# ATSAMA5D26 register map
Vendor: Microchip Technology; Series: SAMA5D2; File version: 0
Registers are 32-bit, read-write, reset 0x0 unless marked. A register's access mark holds for its fields unless they carry their own. Offsets are from the block's base; [hi:lo] are bit positions; {n}, {i} and the like mark numbered series.

## CLASSD — Audio Class D Amplifier (CLASSD)
Base 0xFC048000
0x00 CR wo — Control Register
  [0] SWRST — Software Reset
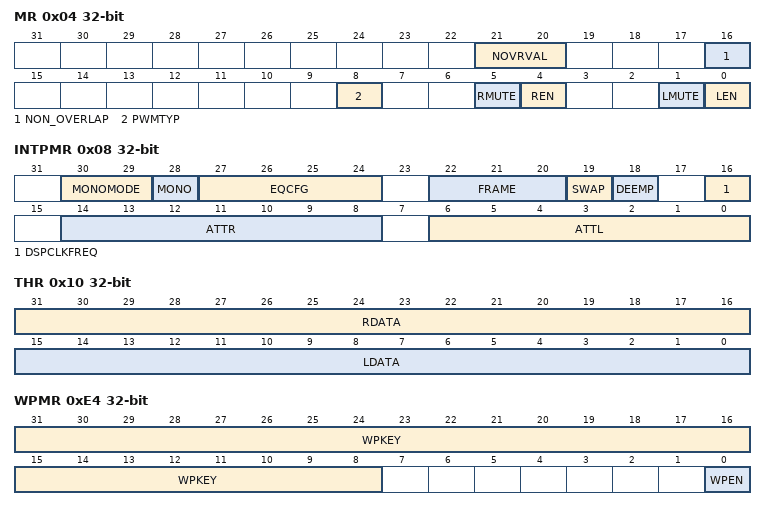
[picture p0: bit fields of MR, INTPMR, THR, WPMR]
0x04 MR — Mode Register
  [21:20] NOVRVAL — Non-Overlapping Value
    0=_5NS (Non-overlapping time is 5 ns); 1=_10NS (Non-overlapping time is 10 ns); 2=_15NS (Non-overlapping time is 15 ns); 3=_20NS (Non-overlapping time is 20 ns)
  [16] NON_OVERLAP — Non-Overlapping Enable
  [8] PWMTYP — PWM Modulation Type
  [5] RMUTE — Right Channel Mute
  [4] REN — Right Channel Enable
  [1] LMUTE — Left Channel Mute
  [0] LEN — Left Channel Enable
0x08 INTPMR — Interpolator Mode Register
  [30:29] MONOMODE — Mono Mode Selection
    0=MONOMIX ((left + right) / 2 is sent on both channels); 1=MONOSAT ((left + right) is sent to both channels. If the sum is too high, the result is saturated.); 2=MONOLEFT (THR[15:0] is sent on both left and right channels); 3=MONORIGHT (THR[31:16] is sent on both left and right channels)
  [28] MONO — Mono Signal
    0=DISABLED (The signal is sent stereo to the left and right channels.); 1=ENABLED (The same signal is sent on both left and right channels. The sent signal is defined by the MONOMODE field value.)
  [27:24] EQCFG — Equalization Selection
    0=FLAT (Flat Response); 1=BBOOST12 (Bass boost +12 dB); 2=BBOOST6 (Bass boost +6 dB); 3=BCUT12 (Bass cut -12 dB); 4=BCUT6 (Bass cut -6 dB); 5=MBOOST3 (Medium boost +3 dB); 6=MBOOST8 (Medium boost +8 dB); 7=MCUT3 (Medium cut -3 dB); 8=MCUT8 (Medium cut -8 dB); 9=TBOOST12 (Treble boost +12 dB); 10=TBOOST6 (Treble boost +6 dB); 11=TCUT12 (Treble cut -12 dB); 12=TCUT6 (Treble cut -6 dB)
  [22:20] FRAME — CLASSD Incoming Data Sampling Frequency
    0=FRAME_8K (8 kHz); 1=FRAME_16K (16 kHz); 2=FRAME_32K (32 kHz); 3=FRAME_48K (48 kHz); 4=FRAME_96K (96 kHz); 5=FRAME_22K (22.05 kHz); 6=FRAME_44K (44.1 kHz); 7=FRAME_88K (88.2 kHz)
  [19] SWAP — Swap Left and Right Channels
    0=LEFT_ON_LSB (Left channel is on CLASSD_THR[15:0], right channel is on CLASSD_THR[31:16].); 1=RIGHT_ON_LSB (Right channel is on CLASSD_THR[15:0], left channel is on CLASSD_THR[31:16].)
  [18] DEEMP — Enable De-emphasis Filter
    0=DISABLED (De-emphasis filter is disabled.); 1=ENABLED (De-emphasis filter is enabled.)
  [16] DSPCLKFREQ — DSP Clock Frequency
    0=_12M288 (DSP Clock (DSPCLK) is 12.288 MHz.); 1=_11M2896 (DSP Clock (DSPCLK) is 11.2896 MHz.)
  [14:8] ATTR — Right Channel Attenuation
  [6:0] ATTL — Left Channel Attenuation
0x0C INTSR ro — Interpolator Status Register
  [0] CFGERR — Configuration Error
0x10 THR — Transmit Holding Register
  [31:16] RDATA — Right Channel Data
  [15:0] LDATA — Left Channel Data
0x14 IER wo — Interrupt Enable Register
  [0] DATRDY — Data Ready
0x18 IDR wo — Interrupt Disable Register
  [0] DATRDY — Data Ready
0x1C IMR — Interrupt Mask Register
  [0] DATRDY — Data Ready
0x20 ISR ro — Interrupt Status Register
  [0] DATRDY — Data Ready
0xE4 WPMR — Write Protection Mode Register
  [31:8] WPKEY — Write Protection Key
    0x434C44=PASSWD (Writing any other value in this field aborts the write operation of the WPEN bit.Always reads as 0.)
  [0] WPEN — Write Protection Enable

## ICM — Integrity Check Monitor
Base 0xF8040000
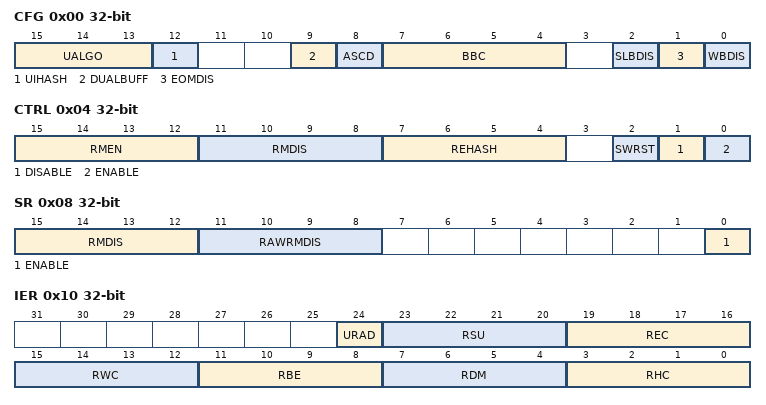
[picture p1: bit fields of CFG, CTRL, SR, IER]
0x00 CFG — Configuration Register
  [15:13] UALGO — User SHA Algorithm
    0=SHA1 (SHA1 algorithm processed); 1=SHA256 (SHA256 algorithm processed); 4=SHA224 (SHA224 algorithm processed)
  [12] UIHASH — User Initial Hash Value
  [9] DUALBUFF — Dual Input Buffer
  [8] ASCD — Automatic Switch To Compare Digest
  [7:4] BBC — Bus Burden Control
  [2] SLBDIS — Secondary List Branching Disable
  [1] EOMDIS — End of Monitoring Disable
  [0] WBDIS — Write Back Disable
0x04 CTRL wo — Control Register
  [15:12] RMEN — Region Monitoring Enable
  [11:8] RMDIS — Region Monitoring Disable
  [7:4] REHASH — Recompute Internal Hash
  [2] SWRST — Software Reset
  [1] DISABLE — ICM Disable Register
  [0] ENABLE — ICM Enable
0x08 SR ro — Status Register
  [15:12] RMDIS — Region Monitoring Disabled Status
  [11:8] RAWRMDIS — Region Monitoring Disabled Raw Status
  [0] ENABLE — ICM Enable Register
0x10 IER wo — Interrupt Enable Register
  [24] URAD — Undefined Register Access Detection Interrupt Enable
  [23:20] RSU — Region Status Updated Interrupt Disable
  [19:16] REC — Region End bit Condition Detected Interrupt Enable
  [15:12] RWC — Region Wrap Condition detected Interrupt Enable
  [11:8] RBE — Region Bus Error Interrupt Enable
  [7:4] RDM — Region Digest Mismatch Interrupt Enable
  [3:0] RHC — Region Hash Completed Interrupt Enable
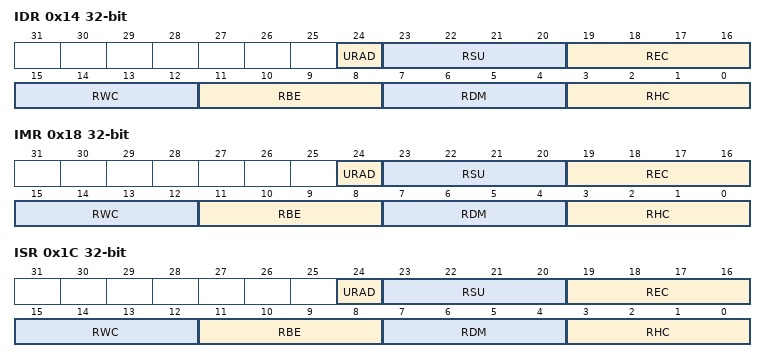
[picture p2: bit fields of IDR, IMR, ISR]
0x14 IDR wo — Interrupt Disable Register
  [24] URAD — Undefined Register Access Detection Interrupt Disable
  [23:20] RSU — Region Status Updated Interrupt Disable
  [19:16] REC — Region End bit Condition detected Interrupt Disable
  [15:12] RWC — Region Wrap Condition Detected Interrupt Disable
  [11:8] RBE — Region Bus Error Interrupt Disable
  [7:4] RDM — Region Digest Mismatch Interrupt Disable
  [3:0] RHC — Region Hash Completed Interrupt Disable
0x18 IMR ro — Interrupt Mask Register
  [24] URAD — Undefined Register Access Detection Interrupt Mask
  [23:20] RSU — Region Status Updated Interrupt Mask
  [19:16] REC — Region End bit Condition Detected Interrupt Mask
  [15:12] RWC — Region Wrap Condition Detected Interrupt Mask
  [11:8] RBE — Region Bus Error Interrupt Mask
  [7:4] RDM — Region Digest Mismatch Interrupt Mask
  [3:0] RHC — Region Hash Completed Interrupt Mask
0x1C ISR ro — Interrupt Status Register
  [24] URAD — Undefined Register Access Detection Status
  [23:20] RSU — Region Status Updated Detected
  [19:16] REC — Region End Bit Condition Detected
  [15:12] RWC — Region Wrap Condition Detected
  [11:8] RBE — Region Bus Error
  [7:4] RDM — Region Digest Mismatch
  [3:0] RHC — Region Hash Completed
0x20 UASR ro — Undefined Access Status Register
  [2:0] URAT — Undefined Register Access Trace
    0=UNSPEC_STRUCT_MEMBER (Unspecified structure member set to one detected when the descriptor is loaded.); 1=ICM_CFG_MODIFIED (ICM_CFG modified during active monitoring.); 2=ICM_DSCR_MODIFIED (ICM_DSCR modified during active monitoring.); 3=ICM_HASH_MODIFIED (ICM_HASH modified during active monitoring); 4=READ_ACCESS (Write-only register read access)
0x30 DSCR — Region Descriptor Area Start Address Register
  [31:6] DASA — Descriptor Area Start Address
0x34 HASH — Region Hash Area Start Address Register
  [31:7] HASA — Hash Area Start Address
{0x38+4i} UIHVAL[{i}] (i=0..7) wo — User Initial Hash Value 0 Register
  [31:0] VAL — Initial Hash Value
